VERSION ""

BS_:

BU_:

// TX20 / CAN ID 0x11A / 282
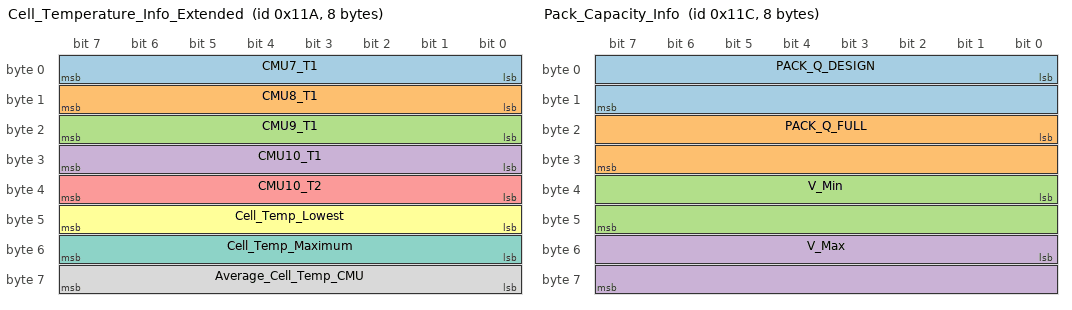
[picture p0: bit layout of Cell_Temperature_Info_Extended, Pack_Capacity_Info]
BO_ 282 Cell_Temperature_Info_Extended: 8 Vector__XXX
 SG_ CMU7_T1           : 0|8@1- (1,0) [-40|125] "C" Vector__XXX
 SG_ CMU8_T1           : 8|8@1- (1,0) [-40|125] "C" Vector__XXX
 SG_ CMU9_T1           : 16|8@1- (1,0) [-40|125] "C" Vector__XXX
 SG_ CMU10_T1          : 24|8@1- (1,0) [-40|125] "C" Vector__XXX
 SG_ CMU10_T2          : 32|8@1- (1,0) [-40|125] "C" Vector__XXX
 SG_ Cell_Temp_Lowest   : 40|8@1- (1,0) [-40|125] "C" Vector__XXX
 SG_ Cell_Temp_Maximum  : 48|8@1- (1,0) [-40|125] "C" Vector__XXX
 SG_ Average_Cell_Temp_CMU : 56|8@1- (1,0) [-40|125] "C" Vector__XXX

// TX14 / CAN ID 0x11C / 284
BO_ 284 Pack_Capacity_Info: 8 Vector__XXX
 SG_ PACK_Q_DESIGN : 0|16@1+ (0.1,0) [0|180] "Ah" Vector__XXX
 SG_ PACK_Q_FULL   : 16|16@1+ (0.1,0) [0|180] "Ah" Vector__XXX
 SG_ V_Min         : 32|16@1+ (0.1,0) [1|4] "mV" Vector__XXX
 SG_ V_Max         : 48|16@1+ (0.1,0) [1|4] "mV" Vector__XXX

// TX11 / CAN ID 0x12A / 298
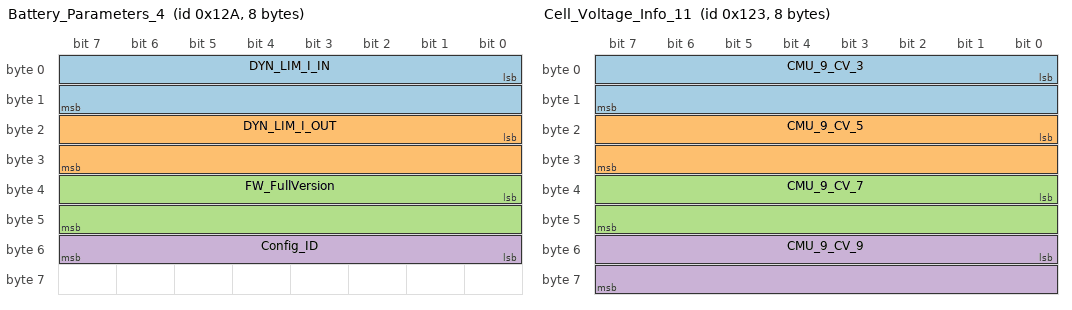
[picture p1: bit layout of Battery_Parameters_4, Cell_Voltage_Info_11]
BO_ 298 Battery_Parameters_4: 8 Vector__XXX
 SG_ DYN_LIM_I_IN : 0|16@1+ (0.1,0) [0|6553.5] "A" Vector__XXX
 SG_ DYN_LIM_I_OUT : 16|16@1+ (0.1,0) [0|6553.5] "A" Vector__XXX
 SG_ FW_FullVersion : 32|16@1+ (1,0) [0|65535] "" Vector__XXX
 SG_ Config_ID : 48|8@1+ (1,0) [0|255] "" Vector__XXX

// TX18 / CAN ID 0x123 / 291
BO_ 291 Cell_Voltage_Info_11: 8 Vector__XXX
 SG_ CMU_9_CV_3 : 0|16@1+ (0.1,0) [0|6553.5] "mV" Vector__XXX
 SG_ CMU_9_CV_5 : 16|16@1+ (0.1,0) [0|6553.5] "mV" Vector__XXX
 SG_ CMU_9_CV_7 : 32|16@1+ (0.1,0) [0|6553.5] "mV" Vector__XXX
 SG_ CMU_9_CV_9 : 48|16@1+ (0.1,0) [0|6553.5] "mV" Vector__XXX

// TX17 / CAN ID 0x122 / 290
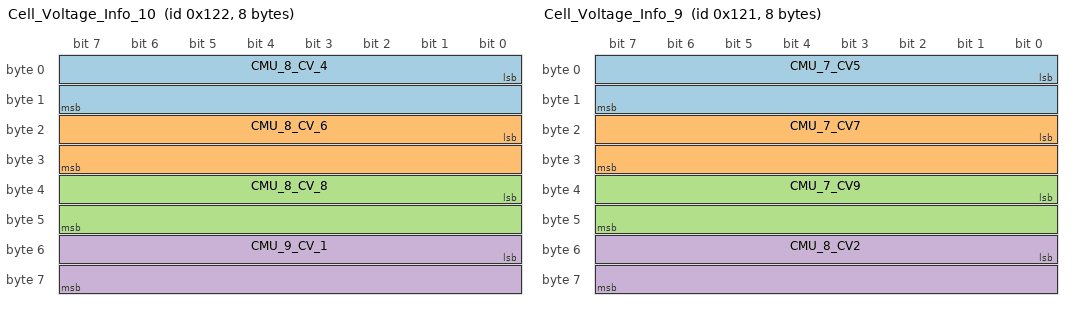
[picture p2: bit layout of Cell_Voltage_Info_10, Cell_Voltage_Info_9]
BO_ 290 Cell_Voltage_Info_10: 8 Vector__XXX
 SG_ CMU_8_CV_4 : 0|16@1+ (0.1,0) [0|6553.5] "mV" Vector__XXX
 SG_ CMU_8_CV_6 : 16|16@1+ (0.1,0) [0|6553.5] "mV" Vector__XXX
 SG_ CMU_8_CV_8 : 32|16@1+ (0.1,0) [0|6553.5] "mV" Vector__XXX
 SG_ CMU_9_CV_1 : 48|16@1+ (0.1,0) [0|6553.5] "mV" Vector__XXX

// TX16 / CAN ID 0x121 / 289
BO_ 289 Cell_Voltage_Info_9: 8 Vector__XXX
 SG_ CMU_7_CV5  : 0|16@1+ (0.1,0) [0|6553.5] "mV" Vector__XXX
 SG_ CMU_7_CV7  : 16|16@1+ (0.1,0) [0|6553.5] "mV" Vector__XXX
 SG_ CMU_7_CV9  : 32|16@1+ (0.1,0) [0|6553.5] "mV" Vector__XXX
 SG_ CMU_8_CV2  : 48|16@1+ (0.1,0) [0|6553.5] "mV" Vector__XXX

// TX15 / CAN ID 0x120 / 288
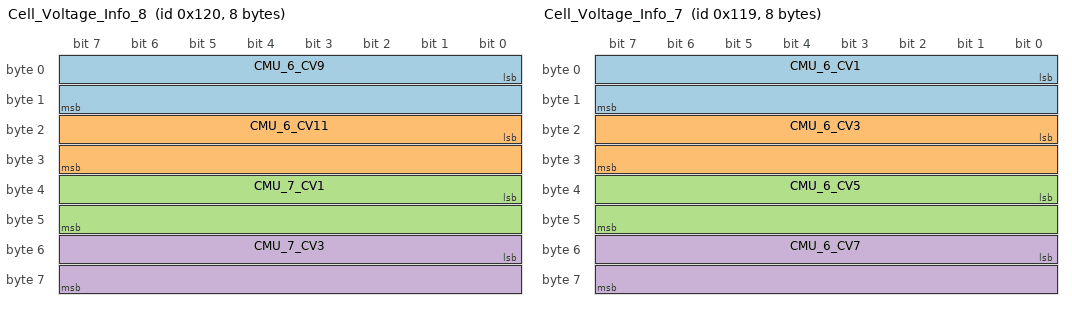
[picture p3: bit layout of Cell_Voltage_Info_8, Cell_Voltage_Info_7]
BO_ 288 Cell_Voltage_Info_8: 8 Vector__XXX
 SG_ CMU_6_CV9  : 0|16@1+ (0.1,0) [0|6553.5] "mV" Vector__XXX
 SG_ CMU_6_CV11 : 16|16@1+ (0.1,0) [0|6553.5] "mV" Vector__XXX
 SG_ CMU_7_CV1  : 32|16@1+ (0.1,0) [0|6553.5] "mV" Vector__XXX
 SG_ CMU_7_CV3  : 48|16@1+ (0.1,0) [0|6553.5] "mV" Vector__XXX

// TX13 / CAN ID 0x11A / 281
BO_ 281 Cell_Voltage_Info_7: 8 Vector__XXX
 SG_ CMU_6_CV1 : 0|16@1+ (0.1,0) [0|6553.5] "mV" Vector__XXX
 SG_ CMU_6_CV3 : 16|16@1+ (0.1,0) [0|6553.5] "mV" Vector__XXX
 SG_ CMU_6_CV5 : 32|16@1+ (0.1,0) [0|6553.5] "mV" Vector__XXX
 SG_ CMU_6_CV7 : 48|16@1+ (0.1,0) [0|6553.5] "mV" Vector__XXX

// TX9 / CAN ID 0x118 / 280
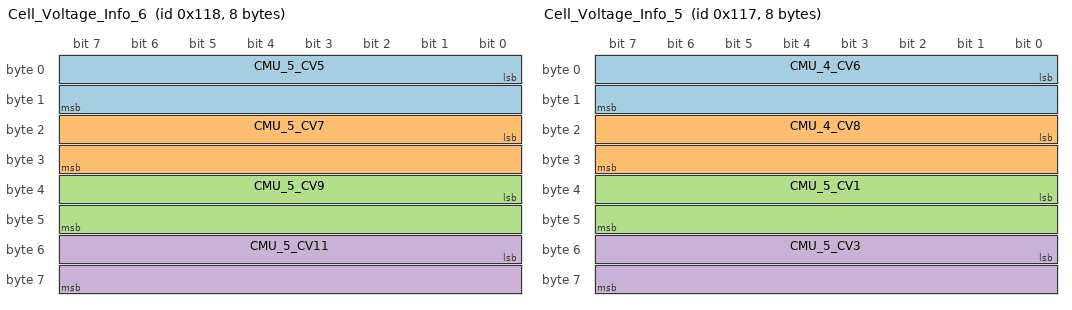
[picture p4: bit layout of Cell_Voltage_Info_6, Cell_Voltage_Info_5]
BO_ 280 Cell_Voltage_Info_6: 8 Vector__XXX
 SG_ CMU_5_CV5 : 0|16@1+ (0.1,0) [0|6553.5] "mV" Vector__XXX
 SG_ CMU_5_CV7 : 16|16@1+ (0.1,0) [0|6553.5] "mV" Vector__XXX
 SG_ CMU_5_CV9 : 32|16@1+ (0.1,0) [0|6553.5] "mV" Vector__XXX
 SG_ CMU_5_CV11 : 48|16@1+ (0.1,0) [0|6553.5] "mV" Vector__XXX

// TX8 / CAN ID 0x117 / 279
BO_ 279 Cell_Voltage_Info_5: 8 Vector__XXX
 SG_ CMU_4_CV6 : 0|16@1+ (0.1,0) [0|6553.5] "mV" Vector__XXX
 SG_ CMU_4_CV8 : 16|16@1+ (0.1,0) [0|6553.5] "mV" Vector__XXX
 SG_ CMU_5_CV1 : 32|16@1+ (0.1,0) [0|6553.5] "mV" Vector__XXX
 SG_ CMU_5_CV3 : 48|16@1+ (0.1,0) [0|6553.5] "mV" Vector__XXX

// TX7 / CAN ID 0x116 / 278
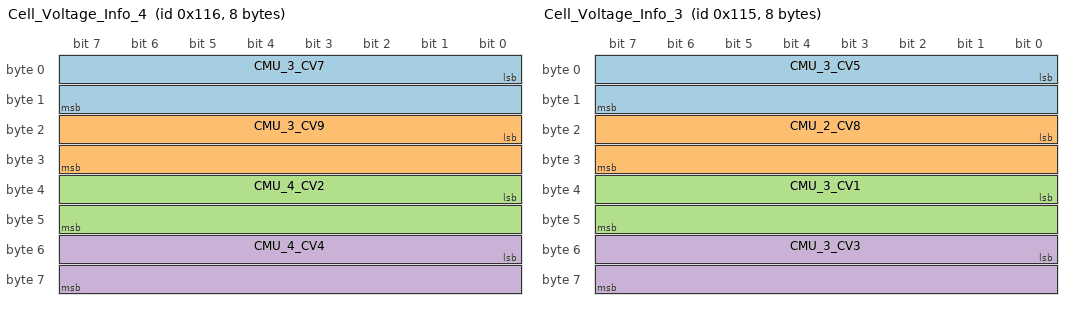
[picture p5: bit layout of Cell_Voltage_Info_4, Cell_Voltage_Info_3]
BO_ 278 Cell_Voltage_Info_4: 8 Vector__XXX
 SG_ CMU_3_CV7 : 0|16@1+ (0.1,0) [0|6553.5] "mV" Vector__XXX
 SG_ CMU_3_CV9 : 16|16@1+ (0.1,0) [0|6553.5] "mV" Vector__XXX
 SG_ CMU_4_CV2 : 32|16@1+ (0.1,0) [0|6553.5] "mV" Vector__XXX
 SG_ CMU_4_CV4 : 48|16@1+ (0.1,0) [0|6553.5] "mV" Vector__XXX

// TX6 / CAN ID 0x115 / 277
BO_ 277 Cell_Voltage_Info_3: 8 Vector__XXX
 SG_ CMU_3_CV5 : 0|16@1+ (0.1,0) [0|6553.5] "mV" Vector__XXX
 SG_ CMU_2_CV8 : 16|16@1+ (0.1,0) [0|6553.5] "mV" Vector__XXX
 SG_ CMU_3_CV1 : 32|16@1+ (0.1,0) [0|6553.5] "mV" Vector__XXX
 SG_ CMU_3_CV3 : 48|16@1+ (0.1,0) [0|6553.5] "mV" Vector__XXX

// TX5 / CAN ID 0x114 / 276
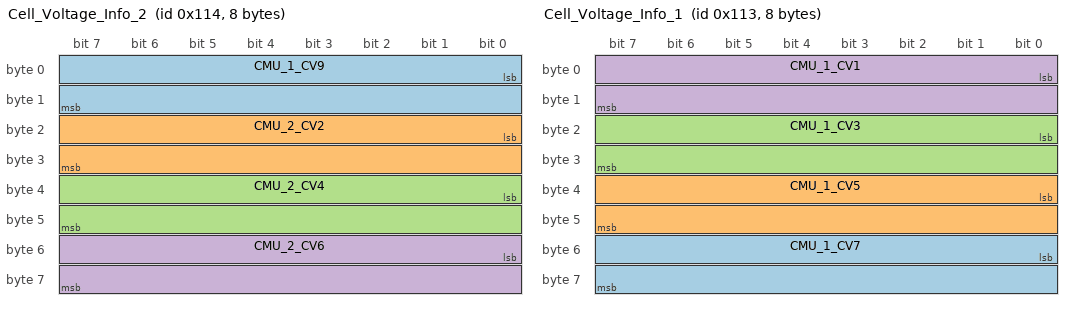
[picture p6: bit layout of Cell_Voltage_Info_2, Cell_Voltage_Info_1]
BO_ 276 Cell_Voltage_Info_2: 8 Vector__XXX
 SG_ CMU_1_CV9 : 0|16@1+ (0.1,0) [0|6553.5] "mV" Vector__XXX
 SG_ CMU_2_CV2 : 16|16@1+ (0.1,0) [0|6553.5] "mV" Vector__XXX
 SG_ CMU_2_CV4 : 32|16@1+ (0.1,0) [0|6553.5] "mV" Vector__XXX
 SG_ CMU_2_CV6 : 48|16@1+ (0.1,0) [0|6553.5] "mV" Vector__XXX

// TX4 / CAN ID 0x113 / 275
BO_ 275 Cell_Voltage_Info_1: 8 Vector__XXX
 SG_ CMU_1_CV7 : 48|16@1+ (0.1,0) [0|6553.5] "mV" Vector__XXX
 SG_ CMU_1_CV5 : 32|16@1+ (0.1,0) [0|6553.5] "mV" Vector__XXX
 SG_ CMU_1_CV3 : 16|16@1+ (0.1,0) [0|6553.5] "mV" Vector__XXX
 SG_ CMU_1_CV1 : 0|16@1+ (0.1,0) [0|6553.5] "mV" Vector__XXX

// TX3 / CAN ID 0x112 / 274
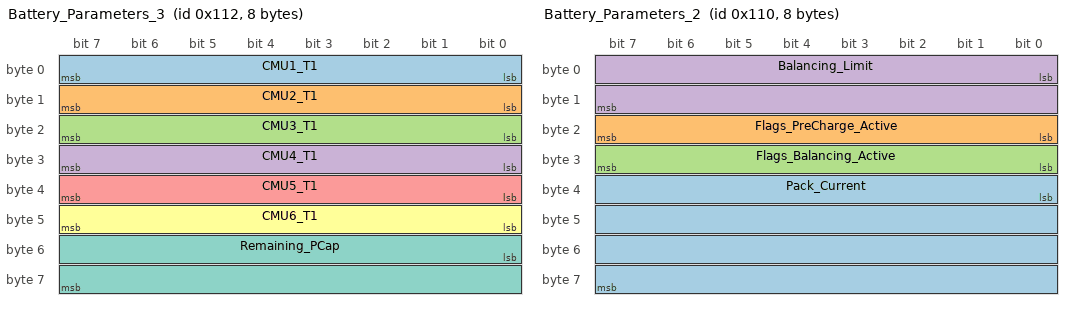
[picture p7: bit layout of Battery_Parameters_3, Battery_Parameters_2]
BO_ 274 Battery_Parameters_3: 8 Vector__XXX
 SG_ CMU1_T1 : 0|8@1- (1,0) [-40|125] "C" Vector__XXX
 SG_ CMU2_T1 : 8|8@1- (1,0) [-40|125] "C" Vector__XXX
 SG_ CMU3_T1 : 16|8@1- (1,0) [-40|125] "C" Vector__XXX
 SG_ CMU4_T1 : 24|8@1- (1,0) [-40|125] "C" Vector__XXX
 SG_ CMU5_T1 : 32|8@1- (1,0) [-40|125] "C" Vector__XXX
 SG_ CMU6_T1 : 40|8@1- (1,0) [-40|125] "C" Vector__XXX
 SG_ Remaining_PCap     : 48|16@1+ (0.1,0) [0|180] "Ah" Vector__XXX

// TX1 / CAN ID 0x110 / 272
BO_ 272 Battery_Parameters_2: 8 Vector__XXX
 SG_ Pack_Current : 32|32@1- (1e-005,0) [21474.8|21474.8] "A" Vector__XXX
 SG_ Flags_PreCharge_Active : 16|8@1+ (1,0) [0|255] "" Vector__XXX
 SG_ Flags_Balancing_Active : 24|8@1+ (1,0) [0|255] "" Vector__XXX
 SG_ Balancing_Limit : 0|16@1+ (0.1,0) [0|6553.5] "mV" Vector__XXX

// TX2 / CAN ID 0x109 / 265

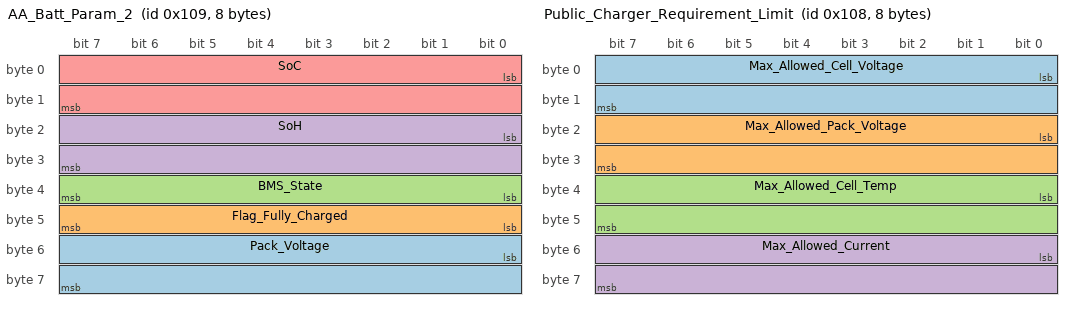
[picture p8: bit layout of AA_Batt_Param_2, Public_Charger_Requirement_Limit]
BO_ 265 AA_Batt_Param_2: 8 Vector__XXX
 SG_ Pack_Voltage : 48|16@1+ (0.1,0) [0|0] "V" Vector__XXX
 SG_ Flag_Fully_Charged : 40|8@1+ (1,0) [0|0] "" Vector__XXX
 SG_ BMS_State : 32|8@1+ (1,0) [0|0] "" Vector__XXX
 SG_ SoH : 16|16@1+ (0.01,0) [0|0] "%" Vector__XXX
 SG_ SoC : 0|16@1+ (0.01,0) [0|0] "%" Vector__XXX

VAL_ 265 Flag_Fully_Charged  0 "False" 1 "True" ;
VAL_ 265 BMS_State           0 "INIT" 1 "Ready" 2 "Precharge" 3 "Active" 4 "Error" ;

// TX12 / CAN ID 0x108 / 264
BO_ 264 Public_Charger_Requirement_Limit: 8 Vector__XXX
 SG_ Max_Allowed_Cell_Voltage : 0|16@1+ (1,0) [0|65535] "mV" Vector__XXX
 SG_ Max_Allowed_Pack_Voltage : 16|16@1+ (1,0) [0|65535] "V" Vector__XXX
 SG_ Max_Allowed_Cell_Temp : 32|16@1+ (1,0) [0|65535] "C" Vector__XXX
 SG_ Max_Allowed_Current : 48|16@1+ (1,0) [0|65535] "A" Vector__XXX

// TX10 / CAN ID 0x107 / 263
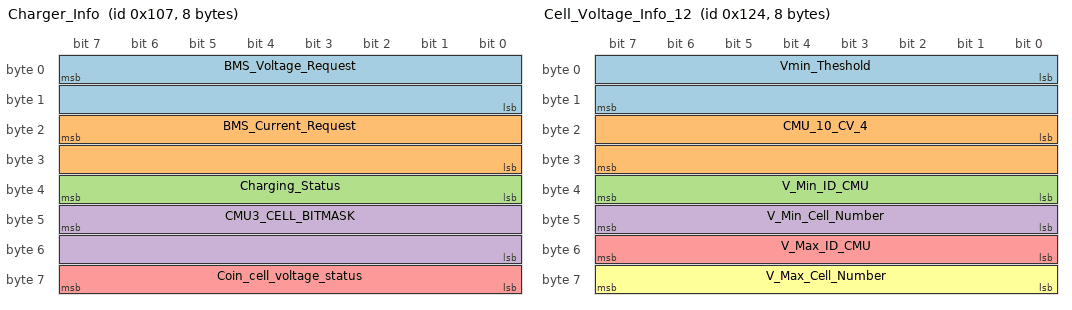
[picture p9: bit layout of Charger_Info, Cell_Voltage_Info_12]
BO_ 263 Charger_Info: 8 Vector__XXX
 SG_ BMS_Voltage_Request : 7|16@0+ (0.1,0) [0|6553.5] "V" Vector__XXX
 SG_ BMS_Current_Request : 23|16@0+ (0.1,0) [0|6553.5] "A" Vector__XXX
 SG_ Charging_Status : 39|8@0+ (1,0) [0|255] "" Vector__XXX
 SG_ CMU3_CELL_BITMASK : 47|16@0+ (1,0) [0|65535] "" Vector__XXX
 SG_ Coin_cell_voltage_status : 63|8@0+ (1,0) [0|255] "" Vector__XXX

// TX19 / CAN ID 0x124 / 292
BO_ 292 Cell_Voltage_Info_12: 8 Vector__XXX
 SG_ Vmin_Theshold   : 0|16@1+ (0.1,0) [0|6553.5] "mV" Vector__XXX
 SG_ CMU_10_CV_4  : 16|16@1+ (0.1,0) [0|6553.5] "mV" Vector__XXX
 SG_ V_Min_ID_CMU         : 32|8@1+ (1,0) [0|255] "" Vector__XXX
 SG_ V_Min_Cell_Number    : 40|8@1+ (1,0) [0|255] "" Vector__XXX
 SG_ V_Max_ID_CMU         : 48|8@1+ (1,0) [0|255] "" Vector__XXX
 SG_ V_Max_Cell_Number    : 56|8@1+ (1,0) [0|255] "" Vector__XXX

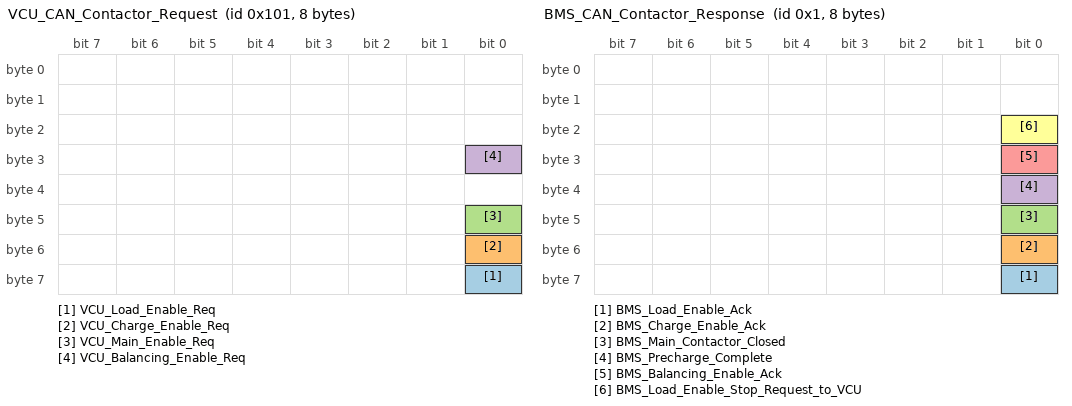
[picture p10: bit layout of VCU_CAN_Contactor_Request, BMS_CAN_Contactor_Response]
BO_ 257 VCU_CAN_Contactor_Request: 8 Vector__XXX
 SG_ VCU_Load_Enable_Req        : 56|1@1+ (1,0) [0|1] "" Vector__XXX
 SG_ VCU_Charge_Enable_Req      : 48|1@1+ (1,0) [0|1] "" Vector__XXX
 SG_ VCU_Main_Enable_Req        : 40|1@1+ (1,0) [0|1] "" Vector__XXX
 SG_ VCU_Balancing_Enable_Req   : 24|1@1+ (1,0) [0|1] "" Vector__XXX

BO_ 1 BMS_CAN_Contactor_Response: 8 Vector__XXX
 SG_ BMS_Load_Enable_Ack                 : 56|1@1+ (1,0) [0|1] "" Vector__XXX
 SG_ BMS_Charge_Enable_Ack               : 48|1@1+ (1,0) [0|1] "" Vector__XXX
 SG_ BMS_Main_Contactor_Closed           : 40|1@1+ (1,0) [0|1] "" Vector__XXX
 SG_ BMS_Precharge_Complete              : 32|1@1+ (1,0) [0|1] "" Vector__XXX
 SG_ BMS_Balancing_Enable_Ack            : 24|1@1+ (1,0) [0|1] "" Vector__XXX
 SG_ BMS_Load_Enable_Stop_Request_to_VCU : 16|1@1+ (1,0) [0|1] "" Vector__XXX

BO_ 600 Active_Error: 8 Vector__XXX
 SG_ Active_error_Count : 40|16@1+ (1,0) [0|65535] "" Vector__XXX

BO_ 602 Error_Code_1: 8 Vector__XXX
 SG_ Error_Code_1 : 55|16@0+ (1,0) [0|65535] "" Vector__XXX

BO_ 603 Error_Code_2: 8 Vector__XXX
 SG_ Error_Code_2 : 55|16@0+ (1,0) [0|65535] "" Vector__XXX

BO_ 604 Error_Code_3: 8 Vector__XXX
 SG_ Error_Code_3 : 55|16@0+ (1,0) [0|65535] "" Vector__XXX

BO_ 605 Error_Code_4: 8 Vector__XXX
 SG_ Error_Code_4 : 55|16@0+ (1,0) [0|65535] "" Vector__XXX

BO_ 606 Error_Code_5: 8 Vector__XXX
 SG_ Error_Code_5 : 55|16@0+ (1,0) [0|65535] "" Vector__XXX

BO_ 607 Error_Code_6: 8 Vector__XXX
 SG_ Error_Code_6 : 55|16@0+ (1,0) [0|65535] "" Vector__XXX

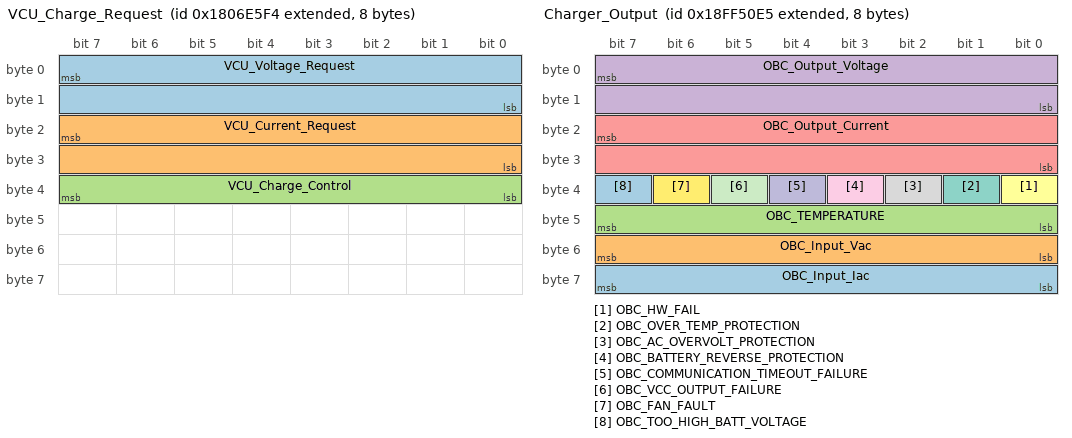
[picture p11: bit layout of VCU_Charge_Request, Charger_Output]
BO_ 2550588916 VCU_Charge_Request: 8 Vector__XXX
 SG_ VCU_Voltage_Request : 7|16@0+ (0.1,0) [0|6553.5] "V" Vector__XXX
 SG_ VCU_Current_Request : 23|16@0+ (0.1,0) [0|6553.5] "A" Vector__XXX
 SG_ VCU_Charge_Control  : 39|8@0+ (1,0) [0|1] "" Vector__XXX

BO_ 2566869221 Charger_Output: 8 Vector__XXX
 SG_ OBC_Input_Iac : 63|8@0+ (0.1,0) [0|25.5] "A" Vector__XXX
 SG_ OBC_Input_Vac : 55|8@0+ (2,0) [0|510] "V" Vector__XXX
 SG_ OBC_TEMPERATURE : 47|8@0+ (1,-100) [-100|155] "°C" Vector__XXX
 SG_ OBC_Output_Voltage : 7|16@0+ (0.1,0) [0|6553.5] "V" Vector__XXX
 SG_ OBC_Output_Current : 23|16@0+ (0.1,0) [0|6553.5] "A" Vector__XXX
 SG_ OBC_HW_FAIL : 32|1@0- (1,0) [0|1] "" Vector__XXX
 SG_ OBC_OVER_TEMP_PROTECTION : 33|1@0- (1,0) [0|1] "" Vector__XXX
 SG_ OBC_AC_OVERVOLT_PROTECTION : 34|1@0- (1,0) [0|1] "" Vector__XXX
 SG_ OBC_BATTERY_REVERSE_PROTECTION : 35|1@0- (1,0) [0|1] "" Vector__XXX
 SG_ OBC_COMMUNICATION_TIMEOUT_FAILURE : 36|1@0- (1,0) [0|1] "" Vector__XXX
 SG_ OBC_VCC_OUTPUT_FAILURE : 37|1@0- (1,0) [0|1] "" Vector__XXX
 SG_ OBC_FAN_FAULT : 38|1@0- (1,0) [0|1] "" Vector__XXX
 SG_ OBC_TOO_HIGH_BATT_VOLTAGE : 39|1@0- (1,0) [0|1] "" Vector__XXX

BO_ 3221225472 VECTOR__INDEPENDENT_SIG_MSG: 0 Vector__XXX
 SG_ MCU_F_RESERVE : 0|2@1+ (1,0) [0|0] "" Vector__XXX

BO_ 1798 MCU_VCU_706: 1 Vector__XXX
 SG_ Regeneration_Active : 10|1@1+ (1,0) [0|0] "" Vector__XXX

BO_ 1830 MCU_VCU_726: 8 Vector__XXX
 SG_ Firmware_Version : 32|32@1+ (1,0) [0|0] "" Vector__XXX
 SG_ Configuration_Version : 0|32@1+ (1,0) [0|0] "" Vector__XXX

BO_ 1829 MCU_VCU_725: 2 Vector__XXX
 SG_ Inputs_Brake_Pot : 8|8@1+ (0.1,0) [0|0] "V" Vector__XXX
 SG_ Inputs_Brake_Command : 0|8@1+ (1,0) [0|0] "%" Vector__XXX

BO_ 2349508592 MCU_VCU_C0AA7F0: 8 Vector__XXX
 SG_ MCU_N_FaultNUM : 56|3@1+ (1,0) [0|0] "" Vector__XXX
 SG_ MCU_N_FaultGrade : 52|4@1+ (1,0) [0|0] "" Vector__XXX
 SG_ MCU_F_RESERVE9 : 50|2@1+ (1,0) [0|0] "" Vector__XXX
 SG_ MCU_F_IGBT_HOC_WARNING : 49|1@1+ (1,0) [0|0] "" Vector__XXX
 SG_ MCU_F_ACC_UV_WARNING : 48|1@1+ (1,0) [0|0] "" Vector__XXX
 SG_ MCU_F_RESERVE8 : 47|1@1+ (1,0) [0|0] "" Vector__XXX
 SG_ MCU_F_MOTOR_TEMP_SENSOR : 46|1@1+ (1,0) [0|0] "" Vector__XXX
 SG_ MCU_F_IGBT_TEMP_SENSOR : 45|1@1+ (1,0) [0|0] "" Vector__XXX
 SG_ MCU_F_H_W_OC : 44|1@1+ (1,0) [0|0] "" Vector__XXX
 SG_ MCU_F_H_V_OC : 43|1@1+ (1,0) [0|0] "" Vector__XXX
 SG_ MCU_F_H_U_OC : 42|1@1+ (1,0) [0|0] "" Vector__XXX
 SG_ MCU_F_RESERVE7 : 41|1@1+ (1,0) [0|0] "" Vector__XXX
 SG_ MCU_F_W_DOWN_IGBT : 40|1@1+ (1,0) [0|0] "" Vector__XXX
 SG_ MCU_F_W_UP_IGBT : 39|1@1+ (1,0) [0|0] "" Vector__XXX
 SG_ MCU_F_V_DOWN_IGBT : 38|1@1+ (1,0) [0|0] "" Vector__XXX
 SG_ MCU_F_V_UP_IGBT : 37|1@1+ (1,0) [0|0] "" Vector__XXX
 SG_ MCU_F_U_DOWN_IGBT : 36|1@1+ (1,0) [0|0] "" Vector__XXX
 SG_ MCU_F_U_UP_IGBT : 35|1@1+ (1,0) [0|0] "" Vector__XXX
 SG_ MCU_F_RESERVE6 : 31|4@1+ (1,0) [0|0] "" Vector__XXX
 SG_ MCU_F_MOTOR_OT_H : 30|1@1+ (1,0) [0|0] "" Vector__XXX
 SG_ MCU_F_MOTOR_OT_L : 29|1@1+ (1,0) [0|0] "" Vector__XXX
 SG_ MCU_F_RESERVE5 : 25|4@1+ (1,0) [0|0] "" Vector__XXX
 SG_ MCU_F_IGBT_OT_H : 24|1@1+ (1,0) [0|0] "" Vector__XXX
 SG_ MCU_F_IGBT_OT_L : 23|1@1+ (1,0) [0|0] "" Vector__XXX
 SG_ MCU_F_CAN_OFFLINE : 22|1@1+ (1,0) [0|0] "" Vector__XXX
 SG_ MCU_F_SPEED_OV : 21|1@1+ (1,0) [0|0] "" Vector__XXX
 SG_ MCU_F_RESERVE4 : 19|2@1+ (1,0) [0|0] "" Vector__XXX
 SG_ MCU_F_CONTROL_OL_H : 18|1@1+ (1,0) [0|0] "" Vector__XXX
 SG_ MCU_F_CONTROL_OL_L : 17|1@1+ (1,0) [0|0] "" Vector__XXX
 SG_ MCU_F_BUS_OV_H : 16|1@1+ (1,0) [0|0] "" Vector__XXX
 SG_ MCU_F_BUS_OV_L : 15|1@1+ (1,0) [0|0] "" Vector__XXX
 SG_ MCU_F_BUS_UV_H : 14|1@1+ (1,0) [0|0] "" Vector__XXX
 SG_ MCU_F_BUS_UV_L : 13|1@1+ (1,0) [0|0] "" Vector__XXX
 SG_ MCU_F_S_OC : 12|1@1+ (1,0) [0|0] "" Vector__XXX
 SG_ MCU_F_ACC_UV : 11|1@1+ (1,0) [0|0] "" Vector__XXX
 SG_ MCU_F_GUN_SELF : 10|1@1+ (1,0) [0|0] "" Vector__XXX
 SG_ MCU_F_RESERVE3 : 8|2@1+ (1,0) [0|0] "" Vector__XXX
 SG_ MCU_F_CURRENT_DETECT : 7|1@1+ (1,0) [0|0] "" Vector__XXX
 SG_ MCU_F_LACK_PHASE : 6|1@1+ (1,0) [0|0] "" Vector__XXX
 SG_ MCU_F_ENCORDE : 5|1@1+ (1,0) [0|0] "" Vector__XXX
 SG_ MCU_F_RESERVE2 : 4|1@1+ (1,0) [0|0] "" Vector__XXX
 SG_ MCU_F_H_OV : 3|1@1+ (1,0) [0|0] "" Vector__XXX
 SG_ MCU_F_RESERVE1 : 2|1@1+ (1,0) [0|0] "" Vector__XXX
 SG_ MCU_F_H_OC : 1|1@1+ (1,0) [0|0] "" Vector__XXX
 SG_ MCU_F_IGBT : 0|1@1+ (1,0) [0|0] "" Vector__XXX

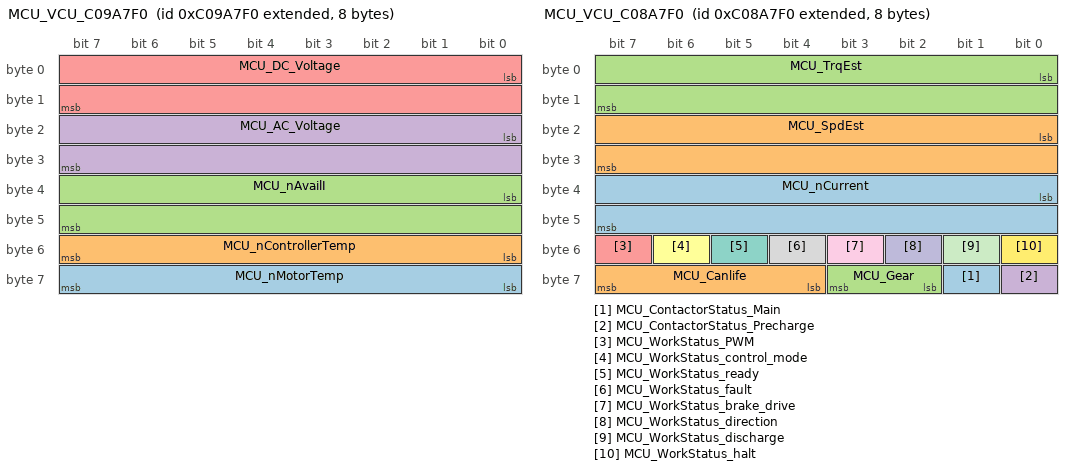
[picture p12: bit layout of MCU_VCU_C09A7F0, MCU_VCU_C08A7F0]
BO_ 2349443056 MCU_VCU_C09A7F0: 8 Vector__XXX
 SG_ MCU_nMotorTemp : 56|8@1+ (1,-40) [0|0] "¡ãC" Vector__XXX
 SG_ MCU_nControllerTemp : 48|8@1+ (1,-40) [0|0] "¡ãC" Vector__XXX
 SG_ MCU_nAvailI : 32|16@1+ (0.1,0) [0|0] "A" Vector__XXX
 SG_ MCU_AC_Voltage : 16|16@1+ (0.1,0) [0|0] "V" Vector__XXX
 SG_ MCU_DC_Voltage : 0|16@1+ (0.1,0) [0|0] "V" Vector__XXX

BO_ 2349377520 MCU_VCU_C08A7F0: 8 Vector__XXX
 SG_ MCU_ContactorStatus_Main : 57|1@1+ (1,0) [0|0] "" Vector__XXX
 SG_ MCU_Canlife : 60|4@1+ (1,0) [0|0] "" Vector__XXX
 SG_ MCU_Gear : 58|2@1+ (1,0) [0|0] "" Vector__XXX
 SG_ MCU_ContactorStatus_Precharge : 56|1@1+ (1,0) [0|0] "" Vector__XXX
 SG_ MCU_WorkStatus_PWM : 55|1@1+ (1,0) [0|0] "" Vector__XXX
 SG_ MCU_WorkStatus_control_mode : 54|1@1+ (1,0) [0|0] "" Vector__XXX
 SG_ MCU_WorkStatus_ready : 53|1@1+ (1,0) [0|0] "" Vector__XXX
 SG_ MCU_WorkStatus_fault : 52|1@1+ (1,0) [0|0] "" Vector__XXX
 SG_ MCU_WorkStatus_brake_drive : 51|1@1+ (1,0) [0|0] "" Vector__XXX
 SG_ MCU_WorkStatus_direction : 50|1@1+ (1,0) [0|0] "" Vector__XXX
 SG_ MCU_WorkStatus_discharge : 49|1@1+ (1,0) [0|0] "" Vector__XXX
 SG_ MCU_WorkStatus_halt : 48|1@1+ (1,0) [0|0] "" Vector__XXX
 SG_ MCU_nCurrent : 32|16@1+ (0.1,-3200) [0|0] "A" Vector__XXX
 SG_ MCU_SpdEst : 16|16@1+ (1,-32000) [0|0] "rpm" Vector__XXX
 SG_ MCU_TrqEst : 0|16@1+ (0.1,-3200) [0|0] "Nm" Vector__XXX

BO_ 2349330599 VCU_MCU_C07F0A7: 6 Vector__XXX
 SG_ VCU_Canlife : 60|4@1+ (1,0) [0|0] "" Vector__XXX
 SG_ VCU_HVCircuit : 42|2@1+ (1,0) [0|0] "" Vector__XXX
 SG_ VCU_Discharge : 41|1@1+ (1,0) [0|0] "" Vector__XXX
 SG_ VCU_Enable : 40|1@1+ (1,0) [0|0] "" Vector__XXX
 SG_ VCU_ModeReq_control_mode : 37|1@1+ (1,0) [0|0] "" Vector__XXX
 SG_ VCU_ModeReq_reverse : 36|1@1+ (1,0) [0|0] "" Vector__XXX
 SG_ VCU_ModeReq_brake : 35|1@1+ (1,0) [0|0] "" Vector__XXX
 SG_ VCU_ModeReq_forward : 34|1@1+ (1,0) [0|0] "" Vector__XXX
 SG_ VCU_ModeReq_idle : 33|1@1+ (1,0) [0|0] "" Vector__XXX
 SG_ VCU_ModeReq_halt : 32|1@1+ (1,0) [0|0] "" Vector__XXX
 SG_ VCU_SpdReq : 16|16@1+ (1,-32000) [0|0] "rpm" Vector__XXX
 SG_ VCU_TrqReq : 0|16@1+ (0.1,-3200) [0|0] "Nm" Vector__XXX

BO_ 265 BMS_MCU_109: 2 Vector__XXX
 SG_ BMS_Soc : 0|16@1+ (0.01,0) [0|0] "%" Vector__XXX

BO_ 272 BMS_MCU_110: 4 Vector__XXX
 SG_ BMS_Pack_Current : 32|32@1- (1E-005,0) [0|0] "A" Vector__XXX

BO_ 298 BMS_MCU_12A: 4 Vector__XXX
 SG_ BMS_DC_Disharge_Request : 16|16@1+ (0.1,0) [0|0] "A" Vector__XXX
 SG_ BMS_DC_Charge_Request : 0|16@1+ (0.1,0) [0|0] "A" Vector__XXX
